# CY8C5868AXI_LP035 register map
File version: 0.1
CY8C58LP
Registers are 8-bit, read-write, no defined reset value unless marked. A register's access mark holds for its fields unless they carry their own. Offsets are from the block's base; lines under a group give offsets from that group; [hi:lo] are bit positions; {n}, {i} and the like mark numbered series; 'fields as' and 'values as' point back to an identical list; <NAME> marks a mode.

## Memory map
0x4000646A LED_Register size 0x31
0x4000646F Seven_Segment_Register size 0x31
0x4000647A PushButton_Register size 0x1
0x4000647E TFTSHIELD_1_CR_1 size 0x1
0x4000647F Switch_Register size 0x1

## TFTSHIELD_1_CR_1
Base 0x4000647E
0x00 TFTSHIELD_1_CR_1_CONTROL_REG

## Seven_Segment_Register
Base 0x4000646F
0x00 Seven_Segment_Register_STATUS_REG
0x20 Seven_Segment_Register_MASK_REG
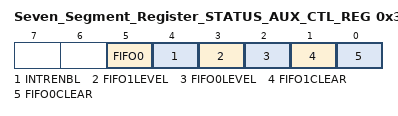
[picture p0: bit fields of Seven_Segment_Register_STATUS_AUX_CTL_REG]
0x30 Seven_Segment_Register_STATUS_AUX_CTL_REG
  [5] FIFO0 — FIFO0 clear
    1=ENABLED (Enable counter); 0=DISABLED (Disable counter)
  [4] INTRENBL — Enables or disables the Interrupt
    1=ENABLED (Interrupt enabled); 0=DISABLED (Interrupt disabled)
  [3] FIFO1LEVEL — FIFO level
    1=ENABLED (FIFO LVL: input mode: FIFO at least 1/2 empty; output mode: FIFO at least 1/2 full); 0=DISABLED (FIFO LVL: input mode: FIFO not full; output mode: FIFO not empty)
  [2] FIFO0LEVEL — FIFO level
    values as FIFO1LEVEL
  [1] FIFO1CLEAR — FIFO clear
    1=ENABLED (Clear FIFO state); 0=DISABLED (Normal FIFO operation)
  [0] FIFO0CLEAR — FIFO clear
    values as FIFO1CLEAR

## LED_Register
Base 0x4000646A
Registers as Seven_Segment_Register (with Seven_Segment_Register read as LED_Register).

## PushButton_Register
Base 0x4000647A
Registers as TFTSHIELD_1_CR_1 (with TFTSHIELD_1_CR_1 read as PushButton_Register).

## Switch_Register
Base 0x4000647F
Registers as TFTSHIELD_1_CR_1 (with TFTSHIELD_1_CR_1 read as Switch_Register).
